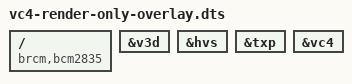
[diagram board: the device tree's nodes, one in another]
/dts-v1/;
/plugin/;

/ {
    compatible = "brcm,bcm2835";

    /*
     * Enable the DRM master, V3D, HVS, and TXP.  Linux VC4 allocates planes
     * against an existing CRTC and its plane setup unconditionally expects
     * the TXP CRTC to be present.  HVS + V3D alone therefore is not a valid
     * component topology and crashes in vc4_plane_create_additional_planes().
     *
     * TXP supplies the smallest headless CRTC/writeback path.  Keep the
     * pixel valves, HDMI, VEC, and firmware-KMS nodes in their base-DTB state
     * so this variant remains focused on render-node registration and V3D
     * command submission rather than physical scanout.
     */
    fragment@0 {
        target = <&v3d>;
        __overlay__ {
            status = "okay";
        };
    };

    fragment@1 {
        target = <&hvs>;
        __overlay__ {
            status = "okay";
        };
    };

    fragment@2 {
        target = <&txp>;
        __overlay__ {
            status = "okay";
        };
    };

    fragment@3 {
        target = <&vc4>;
        __overlay__ {
            status = "okay";
        };
    };
};
